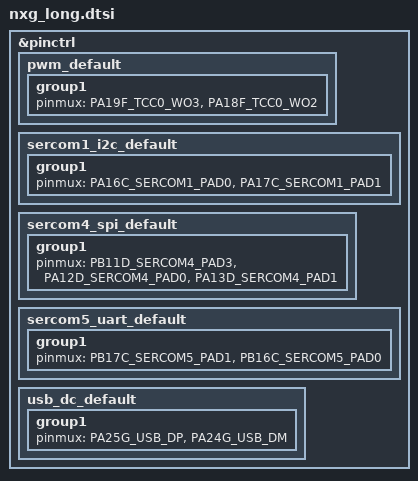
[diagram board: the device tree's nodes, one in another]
#include <dt-bindings/pinctrl/samd21-da1jXabcd-pinctrl.h>

&pinctrl {
	pwm_default: pwm_default {
		group1 {
			pinmux = <PA19F_TCC0_WO3>,
				 <PA18F_TCC0_WO2>;
		};
	};
	sercom1_i2c_default: sercom1_i2c_default {
		group1 {
			pinmux = <PA16C_SERCOM1_PAD0>,
				 <PA17C_SERCOM1_PAD1>;
		};
	};
	sercom4_spi_default: sercom4_spi_default {
		group1 {
			pinmux = <PB11D_SERCOM4_PAD3>, 	// Miso
				 <PA12D_SERCOM4_PAD0>,		// Mosi
				 <PA13D_SERCOM4_PAD1>;		// Sck
		};
	};
	sercom5_uart_default: sercom5_uart_default {
		group1 {
			pinmux = <PB17C_SERCOM5_PAD1>,
				 <PB16C_SERCOM5_PAD0>;
		};
	};
	usb_dc_default: usb_dc_default {
		group1 {
			pinmux = <PA25G_USB_DP>,
				 <PA24G_USB_DM>;
		};
	};
};
